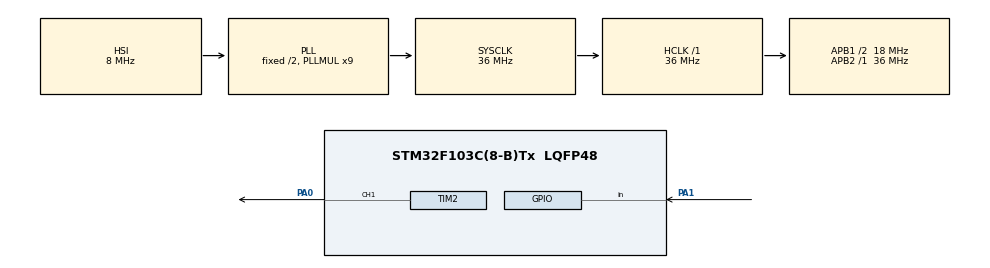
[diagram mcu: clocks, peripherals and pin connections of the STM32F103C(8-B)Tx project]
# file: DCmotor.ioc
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Mcu.Family=STM32F1
Mcu.Name=STM32F103C(8-B)Tx
Mcu.Package=LQFP48
NVIC.PriorityGroup=NVIC_PRIORITYGROUP_4
PA0-WKUP.Signal=S_TIM2_CH1_ETR
PA1.Signal=GPIO_Input
PA13.Mode=Serial_Wire
PA13.Signal=SYS_JTMS-SWDIO
PA14.Mode=Serial_Wire
PA14.Signal=SYS_JTCK-SWCLK
ProjectManager.HeapSize=0x200
ProjectManager.StackSize=0x400
ProjectManager.TargetToolchain=MDK-ARM V5.32
RCC.AHBFreq_Value=36000000
RCC.APB1CLKDivider=RCC_HCLK_DIV2
RCC.APB1Freq_Value=18000000
RCC.APB1TimFreq_Value=36000000
RCC.APB2Freq_Value=36000000
RCC.APB2TimFreq_Value=36000000
RCC.HCLKFreq_Value=36000000
RCC.PLLMUL=RCC_PLL_MUL9
RCC.SYSCLKFreq_VALUE=36000000
RCC.SYSCLKSource=RCC_SYSCLKSOURCE_PLLCLK
RCC.USBFreq_Value=36000000
SH.S_TIM2_CH1_ETR.0=TIM2_CH1,PWM Generation1 CH1
TIM2.Channel-PWM\ Generation1\ CH1=TIM_CHANNEL_1
TIM2.Period=999
TIM2.Prescaler=35
TIM3.AutoReloadPreload=TIM_AUTORELOAD_PRELOAD_ENABLE
TIM3.Period=999
TIM3.Prescaler=35
VP_TIM2_VS_ClockSourceINT.Mode=Internal
VP_TIM3_VS_ClockSourceINT.Mode=Internal
board=custom

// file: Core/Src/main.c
/* USER CODE BEGIN Header */
/**
  ******************************************************************************
  * @file           : main.c
  * @brief          : Main program body
  ******************************************************************************
  * @attention
  *
  * Copyright (c) 2023 STMicroelectronics.
  * All rights reserved.
  *
  * This software is licensed under terms that can be found in the LICENSE file
  * in the root directory of this software component.
  * If no LICENSE file comes with this software, it is provided AS-IS.
  *
  ******************************************************************************
  */
/* USER CODE END Header */
#include "main.h"

/* USER CODE BEGIN Includes */
int t1, t2, e,i,d,ec;
int n;
/* USER CODE END Includes */

TIM_HandleTypeDef htim2;
TIM_HandleTypeDef htim3;

void SystemClock_Config(void);
static void MX_GPIO_Init(void);
static void MX_TIM2_Init(void);
static void MX_TIM3_Init(void);

int main(void)
    {

  /* MCU Configuration--------------------------------------------------------*/

  /* Reset of all peripherals, Initializes the Flash interface and the Systick. */
  HAL_Init();

  /* Configure the system clock */
  SystemClock_Config();

  /* Initialize all configured peripherals */
  MX_GPIO_Init();
  MX_TIM2_Init();
  MX_TIM3_Init();
  /* USER CODE BEGIN 2 */
	HAL_TIM_PWM_Start(&htim2, TIM_CHANNEL_1);
	HAL_TIM_Base_Start_IT(&htim3);
  /* USER CODE END 2 */
	i=0;
	e=0;
	t2=0;
  /* Infinite loop */
  while (1)
  {
	if(HAL_GPIO_ReadPin(GPIOA, GPIO_PIN_1)==0)
			{
				ec=e;
				t1= t2;
				t2= __HAL_TIM_GetCounter(&htim2);
				e= t2-t1;
				__HAL_TIM_SET_COUNTER(&htim3, 0);
				i=i+(1000-e)*e;
				n= 0.06*(1000-e)+0.0000000001*i+0.00001*(e-ec)/e;
			  __HAL_TIM_SetCompare(&htim2, TIM_CHANNEL_1, n);
				while(HAL_GPIO_ReadPin(GPIOA, GPIO_PIN_1)==1)
				{
				}
			}
  }
}

void SystemClock_Config(void)
{
  RCC_OscInitTypeDef RCC_OscInitStruct = {0};
  RCC_ClkInitTypeDef RCC_ClkInitStruct = {0};

  /** Initializes the RCC Oscillators according to the specified parameters
  * in the RCC_OscInitTypeDef structure.
  */
  RCC_OscInitStruct.OscillatorType = RCC_OSCILLATORTYPE_HSI;
  RCC_OscInitStruct.HSIState = RCC_HSI_ON;
  RCC_OscInitStruct.HSICalibrationValue = RCC_HSICALIBRATION_DEFAULT;
  RCC_OscInitStruct.PLL.PLLState = RCC_PLL_ON;
  RCC_OscInitStruct.PLL.PLLSource = RCC_PLLSOURCE_HSI_DIV2;
  RCC_OscInitStruct.PLL.PLLMUL = RCC_PLL_MUL9;
  if (HAL_RCC_OscConfig(&RCC_OscInitStruct) != HAL_OK)
  {
    Error_Handler();
  }

  /** Initializes the CPU, AHB and APB buses clocks
  */
  RCC_ClkInitStruct.ClockType = RCC_CLOCKTYPE_HCLK|RCC_CLOCKTYPE_SYSCLK
                              |RCC_CLOCKTYPE_PCLK1|RCC_CLOCKTYPE_PCLK2;
  RCC_ClkInitStruct.SYSCLKSource = RCC_SYSCLKSOURCE_PLLCLK;
  RCC_ClkInitStruct.AHBCLKDivider = RCC_SYSCLK_DIV1;
  RCC_ClkInitStruct.APB1CLKDivider = RCC_HCLK_DIV2;
  RCC_ClkInitStruct.APB2CLKDivider = RCC_HCLK_DIV1;

  if (HAL_RCC_ClockConfig(&RCC_ClkInitStruct, FLASH_LATENCY_1) != HAL_OK)
  {
    Error_Handler();
  }
}

static void MX_TIM2_Init(void)
{

  TIM_ClockConfigTypeDef sClockSourceConfig = {0};
  TIM_MasterConfigTypeDef sMasterConfig = {0};
  TIM_OC_InitTypeDef sConfigOC = {0};

  htim2.Instance = TIM2;
  htim2.Init.Prescaler = 35;
  htim2.Init.CounterMode = TIM_COUNTERMODE_UP;
  htim2.Init.Period = 999;
  htim2.Init.ClockDivision = TIM_CLOCKDIVISION_DIV1;
  htim2.Init.AutoReloadPreload = TIM_AUTORELOAD_PRELOAD_DISABLE;
  if (HAL_TIM_Base_Init(&htim2) != HAL_OK)
  {
    Error_Handler();
  }
  sClockSourceConfig.ClockSource = TIM_CLOCKSOURCE_INTERNAL;
  if (HAL_TIM_ConfigClockSource(&htim2, &sClockSourceConfig) != HAL_OK)
  {
    Error_Handler();
  }
  if (HAL_TIM_PWM_Init(&htim2) != HAL_OK)
  {
    Error_Handler();
  }
  sMasterConfig.MasterOutputTrigger = TIM_TRGO_RESET;
  sMasterConfig.MasterSlaveMode = TIM_MASTERSLAVEMODE_DISABLE;
  if (HAL_TIMEx_MasterConfigSynchronization(&htim2, &sMasterConfig) != HAL_OK)
  {
    Error_Handler();
  }
  sConfigOC.OCMode = TIM_OCMODE_PWM1;
  sConfigOC.Pulse = 0;
  sConfigOC.OCPolarity = TIM_OCPOLARITY_HIGH;
  sConfigOC.OCFastMode = TIM_OCFAST_DISABLE;
  if (HAL_TIM_PWM_ConfigChannel(&htim2, &sConfigOC, TIM_CHANNEL_1) != HAL_OK)
  {
    Error_Handler();
  }
  HAL_TIM_MspPostInit(&htim2);

}

static void MX_TIM3_Init(void)
{

  TIM_ClockConfigTypeDef sClockSourceConfig = {0};
  TIM_MasterConfigTypeDef sMasterConfig = {0};

  htim3.Instance = TIM3;
  htim3.Init.Prescaler = 35;
  htim3.Init.CounterMode = TIM_COUNTERMODE_UP;
  htim3.Init.Period = 999;
  htim3.Init.ClockDivision = TIM_CLOCKDIVISION_DIV1;
  htim3.Init.AutoReloadPreload = TIM_AUTORELOAD_PRELOAD_ENABLE;
  if (HAL_TIM_Base_Init(&htim3) != HAL_OK)
  {
    Error_Handler();
  }
  sClockSourceConfig.ClockSource = TIM_CLOCKSOURCE_INTERNAL;
  if (HAL_TIM_ConfigClockSource(&htim3, &sClockSourceConfig) != HAL_OK)
  {
    Error_Handler();
  }
  sMasterConfig.MasterOutputTrigger = TIM_TRGO_RESET;
  sMasterConfig.MasterSlaveMode = TIM_MASTERSLAVEMODE_DISABLE;
  if (HAL_TIMEx_MasterConfigSynchronization(&htim3, &sMasterConfig) != HAL_OK)
  {
    Error_Handler();
  }

}

static void MX_GPIO_Init(void)
{
  GPIO_InitTypeDef GPIO_InitStruct = {0};

  /* GPIO Ports Clock Enable */
  __HAL_RCC_GPIOA_CLK_ENABLE();

  /*Configure GPIO pin : PA1 */
  GPIO_InitStruct.Pin = GPIO_PIN_1;
  GPIO_InitStruct.Mode = GPIO_MODE_INPUT;
  GPIO_InitStruct.Pull = GPIO_NOPULL;
  HAL_GPIO_Init(GPIOA, &GPIO_InitStruct);

}

void Error_Handler(void)
{
  __disable_irq();
  while (1)
  {
  }
}
